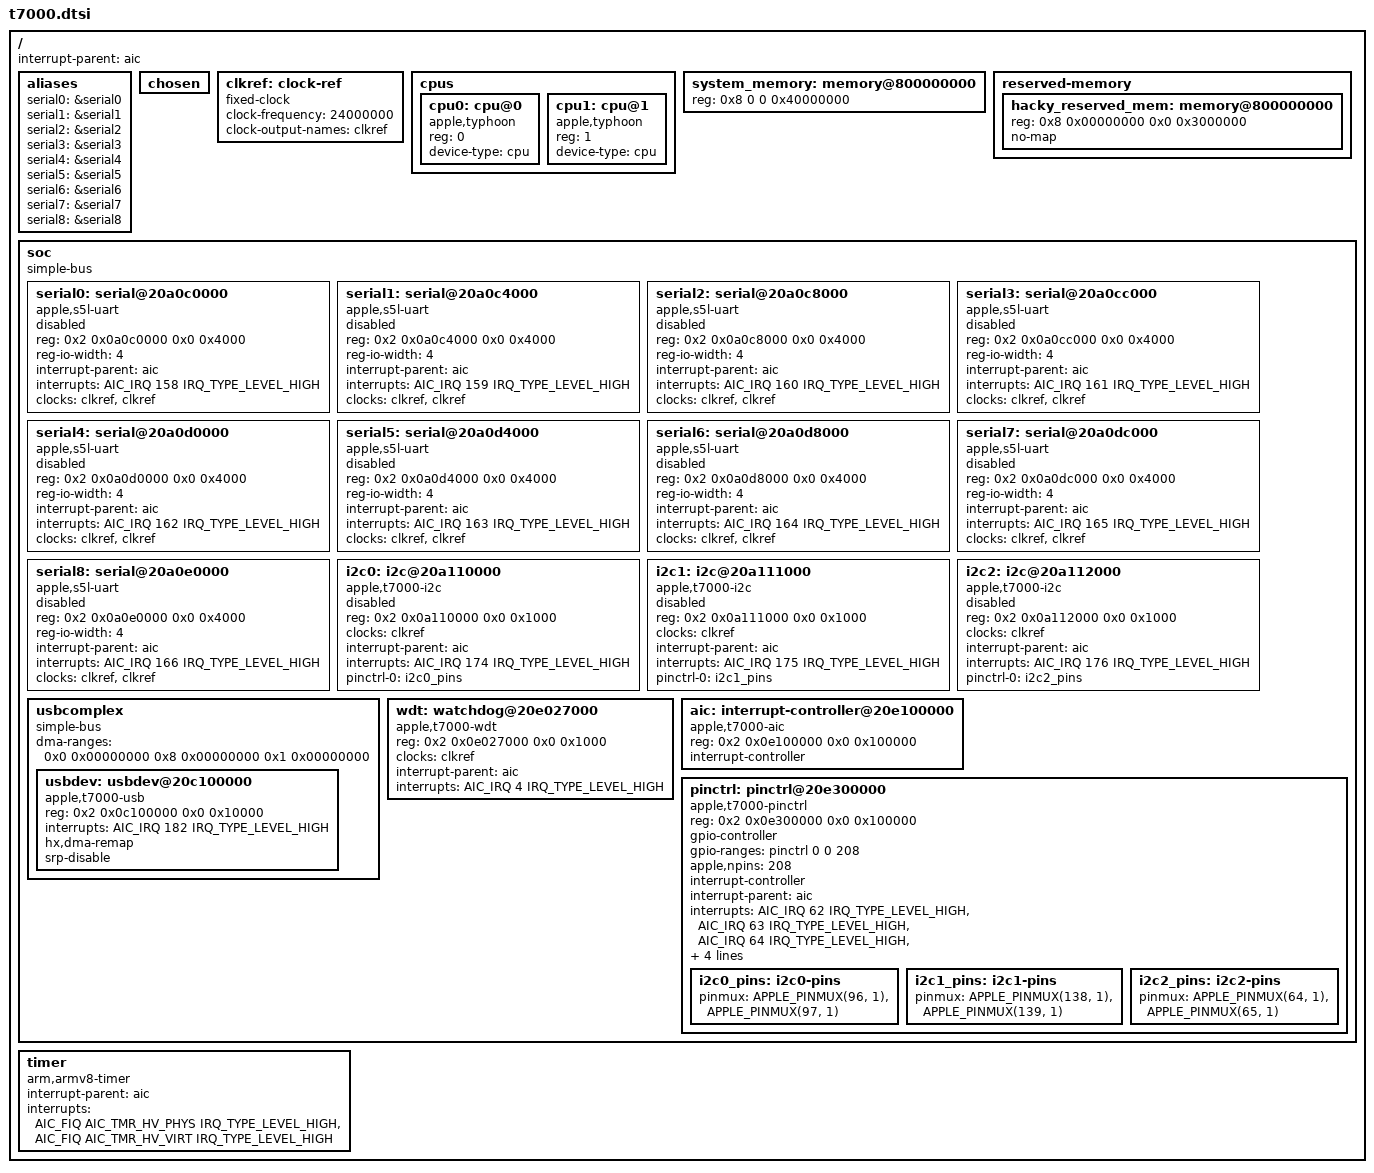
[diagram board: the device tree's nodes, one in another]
// SPDX-License-Identifier: GPL-2.0+ OR MIT
/*
 * Apple T7000 "A8" SoC
 *
 * Copyright (c) 2022, Konrad Dybcio <konrad.dybcio@somainline.org>
 * Based on Asahi Linux's M1 (t8103.dtsi) and Corellium's A10 efforts.
 */

#include <dt-bindings/gpio/gpio.h>
#include <dt-bindings/interrupt-controller/apple-aic.h>
#include <dt-bindings/interrupt-controller/irq.h>
#include <dt-bindings/pinctrl/apple.h>

/ {
	interrupt-parent = <&aic>;
	#address-cells = <2>;
	#size-cells = <2>;

	aliases {
		serial0 = &serial0;
		serial1 = &serial1;
		serial2 = &serial2;
		serial3 = &serial3;
		serial4 = &serial4;
		serial5 = &serial5;
		serial6 = &serial6;
		serial7 = &serial7;
		serial8 = &serial8;
	};

	chosen {
		#address-cells = <2>;
		#size-cells = <2>;
		ranges;
	};

	clkref: clock-ref {
		compatible = "fixed-clock";
		#clock-cells = <0>;
		clock-frequency = <24000000>;
		clock-output-names = "clkref";
	};

	cpus {
		#address-cells = <1>;
		#size-cells = <0>;
		
		cpu0: cpu@0 {
			compatible = "apple,typhoon";
			reg = <0>;
			device-type = "cpu";
		};

		cpu1: cpu@1 {
			compatible = "apple,typhoon";
			reg = <1>;
			device-type = "cpu";
		};
	};

	system_memory: memory@800000000 {
		device_type = "memory";
		/* All A8 devices come with at least 1 GiB of RAM. */
		reg = <0x8 0 0 0x40000000>;
	};

	reserved-memory {
		#address-cells = <2>;
		#size-cells = <2>;
		ranges;

		/* TODO: include proper reservations, this makes it at least boot.. */
		hacky_reserved_mem: memory@800000000 {
			reg = <0x8 0x00000000 0x0 0x3000000>;
			no-map;
		};
	};

	soc {
		compatible = "simple-bus";
		#address-cells = <2>;
		#size-cells = <2>;
		ranges;

		serial0: serial@20a0c0000 {
			compatible = "apple,s5l-uart";
			reg = <0x2 0x0a0c0000 0x0 0x4000>;
			reg-io-width = <4>;
			interrupt-parent = <&aic>;
			interrupts = <AIC_IRQ 158 IRQ_TYPE_LEVEL_HIGH>;
			/* Use the bootloader-enabled clocks for now. */
			clocks = <&clkref>, <&clkref>;
			clock-names = "uart", "clk_uart_baud0";
			status = "disabled";
		};

		serial1: serial@20a0c4000 {
			compatible = "apple,s5l-uart";
			reg = <0x2 0x0a0c4000 0x0 0x4000>;
			reg-io-width = <4>;
			interrupt-parent = <&aic>;
			interrupts = <AIC_IRQ 159 IRQ_TYPE_LEVEL_HIGH>;
			/* Use the bootloader-enabled clocks for now. */
			clocks = <&clkref>, <&clkref>;
			clock-names = "uart", "clk_uart_baud0";
			status = "disabled";
		};

		serial2: serial@20a0c8000 {
			compatible = "apple,s5l-uart";
			reg = <0x2 0x0a0c8000 0x0 0x4000>;
			reg-io-width = <4>;
			interrupt-parent = <&aic>;
			interrupts = <AIC_IRQ 160 IRQ_TYPE_LEVEL_HIGH>;
			/* Use the bootloader-enabled clocks for now. */
			clocks = <&clkref>, <&clkref>;
			clock-names = "uart", "clk_uart_baud0";
			status = "disabled";
		};

		serial3: serial@20a0cc000 {
			compatible = "apple,s5l-uart";
			reg = <0x2 0x0a0cc000 0x0 0x4000>;
			reg-io-width = <4>;
			interrupt-parent = <&aic>;
			interrupts = <AIC_IRQ 161 IRQ_TYPE_LEVEL_HIGH>;
			/* Use the bootloader-enabled clocks for now. */
			clocks = <&clkref>, <&clkref>;
			clock-names = "uart", "clk_uart_baud0";
			status = "disabled";
		};

		serial4: serial@20a0d0000 {
			compatible = "apple,s5l-uart";
			reg = <0x2 0x0a0d0000 0x0 0x4000>;
			reg-io-width = <4>;
			interrupt-parent = <&aic>;
			interrupts = <AIC_IRQ 162 IRQ_TYPE_LEVEL_HIGH>;
			/* Use the bootloader-enabled clocks for now. */
			clocks = <&clkref>, <&clkref>;
			clock-names = "uart", "clk_uart_baud0";
			status = "disabled";
		};

		serial5: serial@20a0d4000 {
			compatible = "apple,s5l-uart";
			reg = <0x2 0x0a0d4000 0x0 0x4000>;
			reg-io-width = <4>;
			interrupt-parent = <&aic>;
			interrupts = <AIC_IRQ 163 IRQ_TYPE_LEVEL_HIGH>;
			/* Use the bootloader-enabled clocks for now. */
			clocks = <&clkref>, <&clkref>;
			clock-names = "uart", "clk_uart_baud0";
			status = "disabled";
		};

		serial6: serial@20a0d8000 {
			compatible = "apple,s5l-uart";
			reg = <0x2 0x0a0d8000 0x0 0x4000>;
			reg-io-width = <4>;
			interrupt-parent = <&aic>;
			interrupts = <AIC_IRQ 164 IRQ_TYPE_LEVEL_HIGH>;
			/* Use the bootloader-enabled clocks for now. */
			clocks = <&clkref>, <&clkref>;
			clock-names = "uart", "clk_uart_baud0";
			status = "disabled";
		};

		serial7: serial@20a0dc000 {
			compatible = "apple,s5l-uart";
			reg = <0x2 0x0a0dc000 0x0 0x4000>;
			reg-io-width = <4>;
			interrupt-parent = <&aic>;
			interrupts = <AIC_IRQ 165 IRQ_TYPE_LEVEL_HIGH>;
			/* Use the bootloader-enabled clocks for now. */
			clocks = <&clkref>, <&clkref>;
			clock-names = "uart", "clk_uart_baud0";
			status = "disabled";
		};

		serial8: serial@20a0e0000 {
			compatible = "apple,s5l-uart";
			reg = <0x2 0x0a0e0000 0x0 0x4000>;
			reg-io-width = <4>;
			interrupt-parent = <&aic>;
			interrupts = <AIC_IRQ 166 IRQ_TYPE_LEVEL_HIGH>;
			/* Use the bootloader-enabled clocks for now. */
			clocks = <&clkref>, <&clkref>;
			clock-names = "uart", "clk_uart_baud0";
			status = "disabled";
		};

		i2c0: i2c@20a110000 {
			compatible = "apple,t7000-i2c", "apple,i2c";
			reg = <0x2 0x0a110000 0x0 0x1000>;
			clocks = <&clkref>;
			interrupt-parent = <&aic>;
			interrupts = <AIC_IRQ 174 IRQ_TYPE_LEVEL_HIGH>;
			pinctrl-0 = <&i2c0_pins>;
			pinctrl-names = "default";
			#address-cells = <1>;
			#size-cells = <0>;
			status = "disabled";
		};

		i2c1: i2c@20a111000 {
			compatible = "apple,t7000-i2c", "apple,i2c";
			reg = <0x2 0x0a111000 0x0 0x1000>;
			clocks = <&clkref>;
			interrupt-parent = <&aic>;
			interrupts = <AIC_IRQ 175 IRQ_TYPE_LEVEL_HIGH>;
			pinctrl-0 = <&i2c1_pins>;
			pinctrl-names = "default";
			#address-cells = <1>;
			#size-cells = <0>;
			status = "disabled";
		};

		i2c2: i2c@20a112000 {
			compatible = "apple,t7000-i2c", "apple,i2c";
			reg = <0x2 0x0a112000 0x0 0x1000>;
			clocks = <&clkref>;
			interrupt-parent = <&aic>;
			interrupts = <AIC_IRQ 176 IRQ_TYPE_LEVEL_HIGH>;
			pinctrl-0 = <&i2c2_pins>;
			pinctrl-names = "default";
			#address-cells = <1>;
			#size-cells = <0>;
			status = "disabled";
		};

		usbcomplex {
			compatible = "simple-bus";
			#address-cells = <2>;
			#size-cells = <2>;
			dma-ranges = <0x0 0x00000000 0x8 0x00000000 0x1 0x00000000>;
			ranges;

			usbdev: usbdev@20c100000 {
				compatible = "apple,t7000-usb";
				reg = <0x2 0x0c100000 0x0 0x10000>;
				interrupts = <AIC_IRQ 182 IRQ_TYPE_LEVEL_HIGH>;
				hx,dma-remap;
				srp-disable;
			};
		};

		wdt: watchdog@20e027000 {
			compatible = "apple,t7000-wdt", "apple,wdt";
			reg = <0x2 0x0e027000 0x0 0x1000>;
			clocks = <&clkref>;
			interrupt-parent = <&aic>;
			interrupts = <AIC_IRQ 4 IRQ_TYPE_LEVEL_HIGH>;
		};

		aic: interrupt-controller@20e100000 {
			compatible = "apple,t7000-aic", "apple,aic";
			reg = <0x2 0x0e100000 0x0 0x100000>;
			#interrupt-cells = <3>;
			interrupt-controller;
		};

		pinctrl: pinctrl@20e300000 {
			compatible = "apple,t7000-pinctrl", "apple,pinctrl";
			reg = <0x2 0x0e300000 0x0 0x100000>;

			gpio-controller;
			#gpio-cells = <2>;
			gpio-ranges = <&pinctrl 0 0 208>;
			apple,npins = <208>;

			interrupt-controller;
			#interrupt-cells = <2>;
			interrupt-parent = <&aic>;
			interrupts = <AIC_IRQ 62 IRQ_TYPE_LEVEL_HIGH>,
				     <AIC_IRQ 63 IRQ_TYPE_LEVEL_HIGH>,
				     <AIC_IRQ 64 IRQ_TYPE_LEVEL_HIGH>,
				     <AIC_IRQ 65 IRQ_TYPE_LEVEL_HIGH>,
				     <AIC_IRQ 66 IRQ_TYPE_LEVEL_HIGH>,
				     <AIC_IRQ 67 IRQ_TYPE_LEVEL_HIGH>,
				     <AIC_IRQ 68 IRQ_TYPE_LEVEL_HIGH>;

			i2c0_pins: i2c0-pins {
				pinmux = <APPLE_PINMUX(96, 1)>, <APPLE_PINMUX(97, 1)>;
			};

			i2c1_pins: i2c1-pins {
				pinmux = <APPLE_PINMUX(138, 1)>, <APPLE_PINMUX(139, 1)>;
			};

			i2c2_pins: i2c2-pins {
				pinmux = <APPLE_PINMUX(64, 1)>, <APPLE_PINMUX(65, 1)>;
			};
		};
	};

	timer {
		compatible = "arm,armv8-timer";
		interrupt-parent = <&aic>;
		interrupt-names = "phys", "virt";
		/* Note that A8/X doesn't actually have a hypervisor (EL2 is not implemented). */
		interrupts = <AIC_FIQ AIC_TMR_HV_PHYS IRQ_TYPE_LEVEL_HIGH>,
			     <AIC_FIQ AIC_TMR_HV_VIRT IRQ_TYPE_LEVEL_HIGH>;
	};
};
